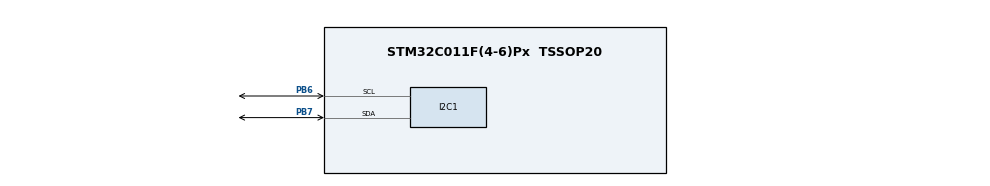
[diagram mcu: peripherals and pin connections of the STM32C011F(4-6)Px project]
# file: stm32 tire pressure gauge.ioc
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I2C1.Timing=0x10805D88
Mcu.Family=STM32C0
Mcu.Name=STM32C011F(4-6)Px
Mcu.Package=TSSOP20
PB6.Mode=I2C
PB6.Signal=I2C1_SCL
PB7.Mode=I2C
PB7.Signal=I2C1_SDA
ProjectManager.HeapSize=0x200
ProjectManager.StackSize=0x400
ProjectManager.TargetToolchain=STM32CubeIDE
RCC.ADCFreq_Value=48000000
RCC.AHBFreq_Value=48000000
RCC.CortexFreq_Value=48000000
RCC.EXTERNAL_CLOCK_VALUE=12288000
RCC.HCLKFreq_Value=48000000
RCC.HSE_VALUE=8000000
RCC.HSISYSCLKDivider=RCC_HSI_DIV1
RCC.HSI_VALUE=48000000
RCC.LSE_VALUE=32768
RCC.SYSCLKFreq_VALUE=48000000
board=custom

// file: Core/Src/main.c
/* USER CODE BEGIN Header */
/**
  ******************************************************************************
  * @file           : main.c
  * @brief          : Main program body
  ******************************************************************************
  * @attention
  *
  * Copyright (c) 2025 STMicroelectronics.
  * All rights reserved.
  *
  * This software is licensed under terms that can be found in the LICENSE file
  * in the root directory of this software component.
  * If no LICENSE file comes with this software, it is provided AS-IS.
  *
  ******************************************************************************
  */
/* USER CODE END Header */
#include "main.h"

/* USER CODE BEGIN Includes */
#include <stdio.h>
#include <stdlib.h>
#include <stdbool.h>
#include <string.h>
#include "ssd1306_conf.h"
#include "ssd1306.h"
#include "ssd1306_fonts.h"
#include "bmp180_for_stm32_hal.h"

/* USER CODE END Includes */

/* USER CODE BEGIN PD */
#define KPA_PSI 0.145038
#define PSI_BAR 0.068947
/* USER CODE END PD */

I2C_HandleTypeDef hi2c1;

/* USER CODE BEGIN PV */
int linha;
//int32_t current_pressure[5], pressure_sum, atm_pressure, avg_pressure[2];
int32_t avg_pressure[2];
char disp_buff[256];
/* USER CODE END PV */

void SystemClock_Config(void);
static void MX_GPIO_Init(void);
static void MX_I2C1_Init(void);

/* USER CODE BEGIN 0 */
void updatePressure()
{
	while (1)
	{
		/*
		atm_pressure = BMP180_GetPressure() * KPA_PSI;
		if (1 < atm_pressure)
		{
			for (int i = 0; i<5; i++)
			{
				current_pressure[i] = BMP180_GetPressure();
				pressure_sum += current_pressure[i];
				HAL_Delay(200);
			}
		}
		else
		{
			avg_pressure_psi = 0;
		}

		avg_pressure_psi = (pressure_sum / 5) * KPA_PSI;
		avg_pressure_bar = avg_pressure_psi * PSI_BAR; */
		avg_pressure[1] = BMP180_GetPressure();

	}
}

void ssd1306_Escrever(uint8_t col, uint8_t linha, char *texto, bool limpar_tela, bool atualizar_tela)
{
  if (limpar_tela)
    ssd1306_Fill(Black);
  ssd1306_SetCursor(col, linha);
  ssd1306_WriteString(texto, Font_7x10, White);
  if (atualizar_tela)
    ssd1306_UpdateScreen();
}

void updateDisplayData()
{
	while (1)
	{
		linha = 0;
		int32_t tempi = BMP180_GetRawTemperature() / 10;
		int32_t tempd = BMP180_GetRawTemperature() % 10;

		//sprintf(psi_buffer, "%ld psi", avg_pressure_psi);
		//sprintf(bar_buffer, "%ld bar", avg_pressure_bar);

		/*ssd1306_Fill(Black);

		ssd1306_SetCursor(0, 0);
		ssd1306_WriteString("Temperatura: ", Font_7x10, White);

		ssd1306_SetCursor(0, 40);
		sprintf((char*)disp_buff, "%ld,%ld", tempi, tempd);
		ssd1306_WriteString(disp_buff, Font_7x10, White);

		ssd1306_SetCursor(16, 0);
		ssd1306_WriteString("Pressao: ", Font_7x10, White);

		ssd1306_SetCursor(16, 40);
		sprintf((char*)disp_buff, "%ld", avg_pressure_psi);
		ssd1306_WriteString(disp_buff, Font_7x10, White);
		ssd1306_UpdateScreen(); */

		ssd1306_Escrever(0, linha+=8, "temperatura: ", true, false);
		sprintf((char*)disp_buff, "%ld,%ld", tempi, tempd);
		ssd1306_Escrever(0, linha+=16, disp_buff, false, false);

		ssd1306_Escrever(0, linha+=8, "pressao: ", false, false);
		sprintf((char*)disp_buff, "%ld kPa", avg_pressure[1]);
		ssd1306_Escrever(0, linha+=16, disp_buff, false, true);

		HAL_Delay(1000);
	}
}
/* USER CODE END 0 */

int main(void)
{

  /* MCU Configuration--------------------------------------------------------*/

  /* Reset of all peripherals, Initializes the Flash interface and the Systick. */
  HAL_Init();

  /* Configure the system clock */
  SystemClock_Config();

  /* Initialize all configured peripherals */
  MX_GPIO_Init();
  MX_I2C1_Init();
  /* USER CODE BEGIN 2 */
  ssd1306_Init();

  BMP180_Init(&hi2c1);
  BMP180_SetOversampling(BMP180_ULTRA);
  BMP180_UpdateCalibrationData();
  /* USER CODE END 2 */

  /* Infinite loop */
  while (1)
  {

    /* USER CODE BEGIN 3 */
	  updatePressure();
	  updateDisplayData();
  }
  /* USER CODE END 3 */
}

void SystemClock_Config(void)
{
  RCC_OscInitTypeDef RCC_OscInitStruct = {0};
  RCC_ClkInitTypeDef RCC_ClkInitStruct = {0};

  __HAL_FLASH_SET_LATENCY(FLASH_LATENCY_1);

  /** Initializes the RCC Oscillators according to the specified parameters
  * in the RCC_OscInitTypeDef structure.
  */
  RCC_OscInitStruct.OscillatorType = RCC_OSCILLATORTYPE_HSI;
  RCC_OscInitStruct.HSIState = RCC_HSI_ON;
  RCC_OscInitStruct.HSIDiv = RCC_HSI_DIV1;
  RCC_OscInitStruct.HSICalibrationValue = RCC_HSICALIBRATION_DEFAULT;
  if (HAL_RCC_OscConfig(&RCC_OscInitStruct) != HAL_OK)
  {
    Error_Handler();
  }

  /** Initializes the CPU, AHB and APB buses clocks
  */
  RCC_ClkInitStruct.ClockType = RCC_CLOCKTYPE_HCLK|RCC_CLOCKTYPE_SYSCLK
                              |RCC_CLOCKTYPE_PCLK1;
  RCC_ClkInitStruct.SYSCLKSource = RCC_SYSCLKSOURCE_HSI;
  RCC_ClkInitStruct.SYSCLKDivider = RCC_SYSCLK_DIV1;
  RCC_ClkInitStruct.AHBCLKDivider = RCC_HCLK_DIV1;
  RCC_ClkInitStruct.APB1CLKDivider = RCC_APB1_DIV1;

  if (HAL_RCC_ClockConfig(&RCC_ClkInitStruct, FLASH_LATENCY_1) != HAL_OK)
  {
    Error_Handler();
  }
}

static void MX_I2C1_Init(void)
{

  hi2c1.Instance = I2C1;
  hi2c1.Init.Timing = 0x10805D88;
  hi2c1.Init.OwnAddress1 = 0;
  hi2c1.Init.AddressingMode = I2C_ADDRESSINGMODE_7BIT;
  hi2c1.Init.DualAddressMode = I2C_DUALADDRESS_DISABLE;
  hi2c1.Init.OwnAddress2 = 0;
  hi2c1.Init.OwnAddress2Masks = I2C_OA2_NOMASK;
  hi2c1.Init.GeneralCallMode = I2C_GENERALCALL_DISABLE;
  hi2c1.Init.NoStretchMode = I2C_NOSTRETCH_DISABLE;
  if (HAL_I2C_Init(&hi2c1) != HAL_OK)
  {
    Error_Handler();
  }

  /** Configure Analogue filter
  */
  if (HAL_I2CEx_ConfigAnalogFilter(&hi2c1, I2C_ANALOGFILTER_ENABLE) != HAL_OK)
  {
    Error_Handler();
  }

  /** Configure Digital filter
  */
  if (HAL_I2CEx_ConfigDigitalFilter(&hi2c1, 0) != HAL_OK)
  {
    Error_Handler();
  }

}

static void MX_GPIO_Init(void)
{

  /* GPIO Ports Clock Enable */
  __HAL_RCC_GPIOB_CLK_ENABLE();

}

void Error_Handler(void)
{
  __disable_irq();
  while (1)
  {
  }
}
